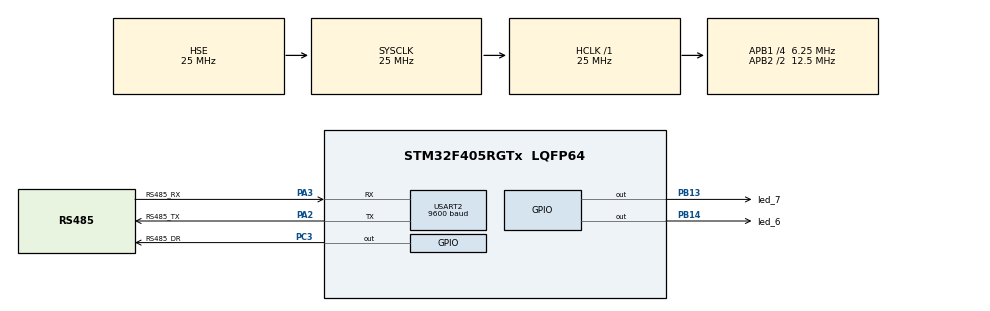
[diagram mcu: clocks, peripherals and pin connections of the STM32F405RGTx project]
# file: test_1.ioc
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Mcu.Family=STM32F4
Mcu.Name=STM32F405RGTx
Mcu.Package=LQFP64
NVIC.PriorityGroup=NVIC_PRIORITYGROUP_4
NVIC.TIM2_IRQn=true\:0\:0\:false\:false\:true\:true\:true
NVIC.USART2_IRQn=true\:0\:0\:false\:false\:true\:true\:true
PA2.GPIO_Label=RS485_TX
PA2.Mode=Asynchronous
PA2.Signal=USART2_TX
PA3.GPIO_Label=RS485_RX
PA3.Mode=Asynchronous
PA3.Signal=USART2_RX
PB13.GPIO_Label=led_7
PB13.Signal=GPIO_Output
PB14.GPIO_Label=led_6
PB14.Signal=GPIO_Output
PC3.GPIO_Label=RS485_DR
PC3.GPIO_Speed=GPIO_SPEED_FREQ_HIGH
PC3.Signal=GPIO_Output
PH0-OSC_IN.Mode=HSE-External-Oscillator
PH0-OSC_IN.Signal=RCC_OSC_IN
PH1-OSC_OUT.Mode=HSE-External-Oscillator
PH1-OSC_OUT.Signal=RCC_OSC_OUT
ProjectManager.HeapSize=0x200
ProjectManager.StackSize=0x400
ProjectManager.TargetToolchain=MDK-ARM V5
RCC.48MHZClocksFreq_Value=36000000
RCC.AHBFreq_Value=25000000
RCC.APB1CLKDivider=RCC_HCLK_DIV4
RCC.APB1Freq_Value=6250000
RCC.APB1TimFreq_Value=12500000
RCC.APB2CLKDivider=RCC_HCLK_DIV2
RCC.APB2Freq_Value=12500000
RCC.APB2TimFreq_Value=25000000
RCC.CortexFreq_Value=25000000
RCC.HCLKFreq_Value=25000000
RCC.HSE_VALUE=25000000
RCC.HSI_VALUE=16000000
RCC.LSE_VALUE=32768
RCC.PLLM=8
RCC.PLLN=72
RCC.PLLP=RCC_PLLP_DIV6
RCC.SYSCLKFreq_VALUE=25000000
RCC.SYSCLKSource=RCC_SYSCLKSOURCE_HSE
RCC.VCOOutputFreq_Value=144000000
TIM2.Period=1000-1
TIM2.Prescaler=25-1
USART2.BaudRate=9600
USART2.VirtualMode=VM_ASYNC
VP_TIM2_VS_ClockSourceINT.Mode=Internal
board=custom

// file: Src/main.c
/* USER CODE BEGIN Header */
/**
  ******************************************************************************
  * @file           : main.c
  * @brief          : Main program body
  ******************************************************************************
  * @attention
  *
  * <h2><center>&copy; Copyright (c) 2023 STMicroelectronics.
  * All rights reserved.</center></h2>
  *
  * This software component is licensed by ST under BSD 3-Clause license,
  * the "License"; You may not use this file except in compliance with the
  * License. You may obtain a copy of the License at:
  *                        opensource.org/licenses/BSD-3-Clause
  *
  ******************************************************************************
  */
/* USER CODE END Header */

#include "main.h"
#include "tim.h"
#include "usart.h"
#include "gpio.h"
#include "rs485.h"

void SystemClock_Config(void);

int main(void)
{
  /* USER CODE BEGIN 1 */
	uint8_t send[3] = "ok";
  /* USER CODE END 1 */

  /* MCU Configuration--------------------------------------------------------*/

  /* Reset of all peripherals, Initializes the Flash interface and the Systick. */
  HAL_Init();

  /* Configure the system clock */
  SystemClock_Config();

  /* Initialize all configured peripherals */
  MX_GPIO_Init();
  MX_USART2_UART_Init();
  MX_TIM2_Init();

  /* Infinite loop */
  while (1)
  {

    /* USER CODE BEGIN 3 */
		HAL_GPIO_TogglePin(GPIOB, GPIO_PIN_13);
		HAL_Delay(1000);
		RS485_SendData(send ,sizeof(send));
		//HAL_GPIO_TogglePin(GPIOB, GPIO_PIN_14);
		//HAL_Delay(1000);
  }
  /* USER CODE END 3 */
}

void SystemClock_Config(void)
{
  RCC_OscInitTypeDef RCC_OscInitStruct = {0};
  RCC_ClkInitTypeDef RCC_ClkInitStruct = {0};

  /** Configure the main internal regulator output voltage
  */
  __HAL_RCC_PWR_CLK_ENABLE();
  __HAL_PWR_VOLTAGESCALING_CONFIG(PWR_REGULATOR_VOLTAGE_SCALE1);
  /** Initializes the CPU, AHB and APB busses clocks
  */
  RCC_OscInitStruct.OscillatorType = RCC_OSCILLATORTYPE_HSE;
  RCC_OscInitStruct.HSEState = RCC_HSE_ON;
  RCC_OscInitStruct.PLL.PLLState = RCC_PLL_NONE;
  if (HAL_RCC_OscConfig(&RCC_OscInitStruct) != HAL_OK)
  {
    Error_Handler();
  }
  /** Initializes the CPU, AHB and APB busses clocks
  */
  RCC_ClkInitStruct.ClockType = RCC_CLOCKTYPE_HCLK|RCC_CLOCKTYPE_SYSCLK
                              |RCC_CLOCKTYPE_PCLK1|RCC_CLOCKTYPE_PCLK2;
  RCC_ClkInitStruct.SYSCLKSource = RCC_SYSCLKSOURCE_HSE;
  RCC_ClkInitStruct.AHBCLKDivider = RCC_SYSCLK_DIV1;
  RCC_ClkInitStruct.APB1CLKDivider = RCC_HCLK_DIV4;
  RCC_ClkInitStruct.APB2CLKDivider = RCC_HCLK_DIV2;

  if (HAL_RCC_ClockConfig(&RCC_ClkInitStruct, FLASH_LATENCY_0) != HAL_OK)
  {
    Error_Handler();
  }
}

void Error_Handler(void)
{
}

/************************ (C) COPYRIGHT STMicroelectronics *****END OF FILE****/
